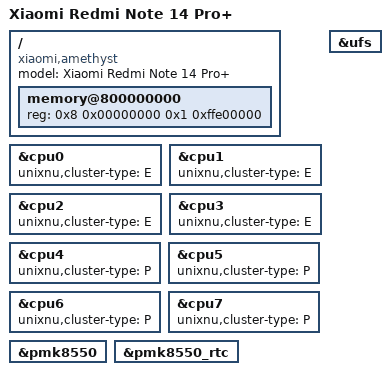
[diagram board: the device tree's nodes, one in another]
// SPDX-License-Identifier: BSD-3-Clause
// Xiaomi Redmi Note 14 Pro+: the board's memory and CPU selection on the shared SM7635 resources.
/dts-v1/;
/include/ "sm7635.dtsi"

/ {
    model = "Xiaomi Redmi Note 14 Pro+";
    compatible = "xiaomi,amethyst", "qcom,volcano";

    memory@800000000 {
        device_type = "memory";
        reg = <0x8 0x00000000  0x1 0xffe00000>;
    };
};

// The scheduler runs the A520 cores as an E cluster and the A720 cores as a P cluster (UniXNU's AMP patch, zzyf).
&cpu0 { unixnu,cluster-type = "E"; };
&cpu1 { unixnu,cluster-type = "E"; };
&cpu2 { unixnu,cluster-type = "E"; };
&cpu3 { unixnu,cluster-type = "E"; };
&cpu4 { unixnu,cluster-type = "P"; };
&cpu5 { unixnu,cluster-type = "P"; };
&cpu6 { unixnu,cluster-type = "P"; };
&cpu7 { unixnu,cluster-type = "P"; };

&ufs { status = "okay"; };

// No SPMI PMIC/RTC driver is selected. These reg values are bus-local IDs,
// not MMIO ranges; the current ADT exporter only supports MMIO peripherals.
// Keep the SoC description, but do not flatten these children into arm-io.
// ponytail: export them when ADT bus-local addressing and its driver exist.
&pmk8550 { /delete-property/ unixnu,adt-name; };
&pmk8550_rtc { /delete-property/ unixnu,adt-name; };
